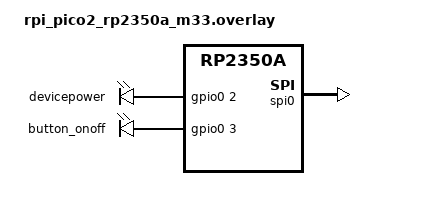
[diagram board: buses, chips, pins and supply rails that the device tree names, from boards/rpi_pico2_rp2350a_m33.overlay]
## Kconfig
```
# SPDX-FileCopyrightText: 2025 Anna-Lena Marx <mail@marx.engineer>
#
# SPDX-License-Identifier: MPL-2.0

menu "ZEReader"

config PIXEL_FORMAT_MONO10
        bool "Reverse display colors"
        default y

# Logging
# use template to create log level configurations
module = ZEREADER
module-str = zereader
source "subsys/logging/Kconfig.template.log_config"

endmenu

source "Kconfig.zephyr"
```

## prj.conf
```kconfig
# SPDX-FileCopyrightText: 2025 Anna-Lena Marx <mail@marx.engineer>
#
# SPDX-License-Identifier: MPL-2.0

# https://docs.zephyrproject.org/latest/kconfig.html

# ZEREADER
CONFIG_ZEREADER_LOG_LEVEL_DBG=y

# General config
CONFIG_GPIO=y

# Maybe needed in future?
# CONFIG_MIPI_DBI=y
# CONFIG_MIPI_DBI_SPI=y

CONFIG_SERIAL=y
# CONFIG_PRINTK=y
CONFIG_LOG=y
# immediate should only be used during development and not for timing critical stuff
CONFIG_LOG_MODE_IMMEDIATE=y
CONFIG_LOG_BACKEND_UART=y
CONFIG_UART_CONSOLE=y


# Config memory
# Make sure the configured stack size matches the size of
# e.g. read buffer arrays!
CONFIG_INIT_STACKS=y
CONFIG_MAIN_STACK_SIZE=10240
CONFIG_HEAP_MEM_POOL_SIZE=50960
CONFIG_IDLE_STACK_SIZE=320
CONFIG_SYSTEM_WORKQUEUE_STACK_SIZE=1024
# CONFIG_ISR_STACK_SIZE=8128
```

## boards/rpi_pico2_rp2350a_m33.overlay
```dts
/*
 * SPDX-FileCopyrightText: 2025 Anna-Lena Marx <mail@marx.engineer>
 *
 * SPDX-License-Identifier: MPL-2.0
 */

#include <zephyr/dt-bindings/input/input-event-codes.h>
#include <zephyr/dt-bindings/lvgl/lvgl.h>

/ {
  aliases {
    pwrpin = &devicepower;
    onoff = &button_onoff;
  };

  powerpin {
    compatible = "gpio-leds";
    devicepower: devpwr {
      gpios = <&gpio0 2 GPIO_ACTIVE_HIGH>;
    };
    button_onoff: button_onoff {
      gpios = <&gpio0 3 GPIO_ACTIVE_HIGH>;
    };
  };

};

&spi0 {
  status = "okay";
};
```

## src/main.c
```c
/*
 * SPDX-FileCopyrightText: 2025 Anna-Lena Marx <mail@marx.engineer>
 *
 * SPDX-License-Identifier: MPL-2.0
 */

#include <stdio.h>
#include <zephyr/logging/log.h>
#include <zephyr/device.h>
#include <zephyr/devicetree.h>
#include <zephyr/drivers/display.h>
#include <zephyr/drivers/gpio.h>
#include <zephyr/kernel.h>

LOG_MODULE_REGISTER(main, CONFIG_ZEREADER_LOG_LEVEL);

#define LONG_PRESS_TIMEOUT K_SECONDS(1)
struct k_timer long_press_timer;

#define PWR DT_ALIAS(pwrpin)
#define ONOFF DT_ALIAS(onoff)
static const struct gpio_dt_spec powerpin = GPIO_DT_SPEC_GET(PWR, gpios);
static const struct gpio_dt_spec onoff_button = GPIO_DT_SPEC_GET(ONOFF, gpios);
static struct gpio_callback button_cb_data;

// static void button_handler(uint32_t button_state, uint32_t has_changed)
// {
//     if (DK_BTN1_MSK & has_changed) {
//         if (DK_BTN1_MSK & button_state) {
//             /* Button changed its state to pressed */
//             k_timer_start(&long_press_timer, LONG_PRESS_TIMEOUT, K_NO_WAIT);
//         } else {
//             /* Button changed its state to released */
//             if (k_timer_status_get(&long_press_timer) > 0) {
//                 /* Timer expired before button was released, indicates long press */
//                 LOG_INF("Long press");
//             } else {
//                 LOG_INF("Short press");
//                 k_timer_stop(&long_press_timer);
//             }
//         }
//     }
// }

void onoff_pressed(const struct device *dev, struct gpio_callback *cb, uint32_t pins)
{
	LOG_DBG("Button pressed!");

}

int main(void)
{
	int ret = 0;

	LOG_DBG("Hello World - ZEReader! %s\n", CONFIG_BOARD_TARGET);

	if (!gpio_is_ready_dt(&powerpin))
	{
		LOG_DBG("Failed 1");
		return 0;
	}
	LOG_DBG("Power Pin ready!");

	ret = gpio_pin_configure_dt(&powerpin, GPIO_OUTPUT_LOW);
	if (ret < 0)
	{
		LOG_DBG("Failed 3");
		return 0;
	}
	LOG_DBG("Power pin configured");
	// LOG_DBG("Alive");
	// gpio_pin_set_dt(&powerpin, 1);

	if (!gpio_is_ready_dt(&onoff_button))
	{
		printk("Error: button device %s is not ready\n",
		       onoff_button.port->name);
		LOG_DBG("Failed 2");
		return 0;
	}
	LOG_DBG("Button ready!");
	ret = gpio_pin_configure_dt(&onoff_button, GPIO_INPUT);
	if (ret < 0)
	{
		LOG_DBG("Failed 4");
		return 0;
	}
	LOG_DBG("Button configured");
	ret = gpio_pin_interrupt_configure_dt(&onoff_button, GPIO_INT_EDGE_TO_ACTIVE);
	if (ret < 0)
	{
		LOG_DBG("Failed 5");
		return 0;
	}

	gpio_init_callback(&button_cb_data, onoff_pressed, BIT(onoff_button.pin));
	gpio_add_callback(onoff_button.port, &button_cb_data);

	LOG_DBG("Interrupt configured");

	k_msleep(2000);
	gpio_pin_set_dt(&powerpin, 1);

	

	// k_msleep(5000);
	// LOG_DBG("Turn off");
	// gpio_pin_set_dt(&powerpin, 0);
	while (1) {
		k_msleep(500);
		LOG_DBG("x");
	}
	
}
```
